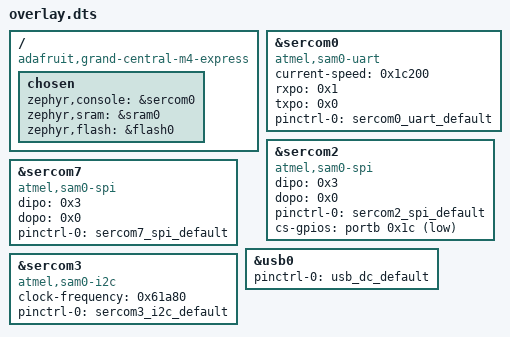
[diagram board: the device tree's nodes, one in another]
/ {
	compatible = "adafruit,grand-central-m4-express";
	chosen {
		zephyr,console = &sercom0;
		zephyr,sram = &sram0;
		zephyr,flash = &flash0;
	};
};
&sercom0{
	compatible = "atmel,sam0-uart";
	status = "okay";
	current-speed = < 0x1c200 >;
	rxpo = < 0x1 >;
	txpo = < 0x0 >;
	pinctrl-0 = < &sercom0_uart_default >;
	pinctrl-names = "default";
};
&sercom2{
	compatible = "atmel,sam0-spi";
	status = "okay";
	dipo = < 0x3 >;
	dopo = < 0x0 >;
	#address-cells = < 0x1 >;
	#size-cells = < 0x0 >;
	pinctrl-0 = < &sercom2_spi_default >;
	pinctrl-names = "default";
	cs-gpios = < &portb 0x1c 0x1 >;
};
&sercom7{
	compatible = "atmel,sam0-spi";
	status = "okay";
	dipo = < 0x3 >;
	dopo = < 0x0 >;
	#address-cells = < 0x1 >;
	#size-cells = < 0x0 >;
	pinctrl-0 = < &sercom7_spi_default >;
	pinctrl-names = "default";
};
&usb0{
	status = "okay";
	pinctrl-0 = < &usb_dc_default >;
	pinctrl-names = "default";
};
&sercom3{
	compatible = "atmel,sam0-i2c";
	status = "okay";
	clock-frequency = < 0x61a80 >;
	#address-cells = < 0x1 >;
	#size-cells = < 0x0 >;
	pinctrl-0 = < &sercom3_i2c_default >;
	pinctrl-names = "default";
};
